# STM32N645 register map
File version: 1.0
CPU: CM55 r0p1, little endian, no MPU, FPU, vendor SysTick, 8 interrupt priority bits
Registers are 32-bit, read-write, reset 0x0 unless marked. A register's access mark holds for its fields unless they carry their own. Offsets are from the block's base; [hi:lo] are bit positions.

## SPDIFRX — SPDIF receiver interface
Base 0x40004000
Same registers: SPDIFRX_S 0x50004000
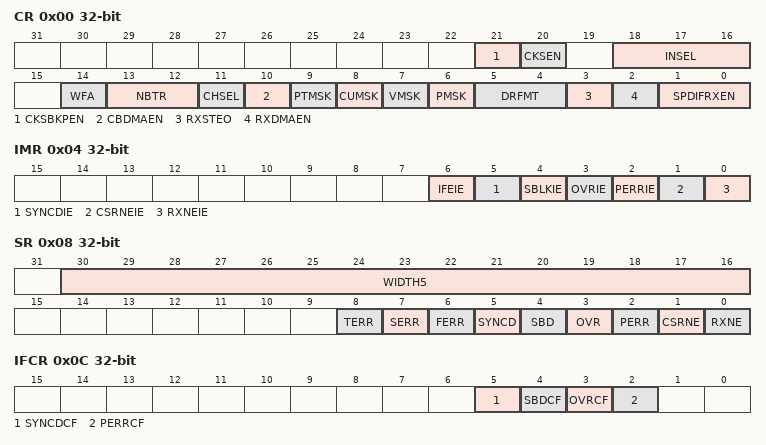
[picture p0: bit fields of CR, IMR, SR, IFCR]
0x00 CR — SPDIFRX control register
  [21] CKSBKPEN — Backup symbol clock enable
  [20] CKSEN — Symbol clock enable
  [18:16] INSEL — SPDIFRX input selection
  [14] WFA — Wait for activity less than sup>(1) less than /sup>
  [13:12] NBTR — Maximum allowed re-tries during synchronization phase less than sup>(1) less than /sup>
  [11] CHSEL — Channel selection less than sup>(1) less than /sup>
  [10] CBDMAEN — Control buffer DMA enable for control flow less than sup>(1) less than /sup>
  [9] PTMSK — Mask of preamble type bits less than sup>(1) less than /sup>
  [8] CUMSK — Mask of channel status and user bits less than sup>(1) less than /sup>
  [7] VMSK — Mask of validity bit less than sup>(1) less than /sup>
  [6] PMSK — Mask parity error bit less than sup>(1) less than /sup>
  [5:4] DRFMT — RX data format less than sup>(1) less than /sup>
  [3] RXSTEO — Stereo mode less than sup>(1) less than /sup>
  [2] RXDMAEN — Receiver DMA enable for data flow less than sup>(1) less than /sup>
  [1:0] SPDIFRXEN — Peripheral block enable less than sup>(1) less than /sup>
0x04 IMR — SPDIFRX interrupt mask register
  [6] IFEIE — Serial interface error interrupt enable
  [5] SYNCDIE — Synchronization done
  [4] SBLKIE — Synchronization block detected interrupt enable
  [3] OVRIE — Overrun error interrupt enable
  [2] PERRIE — Parity error interrupt enable
  [1] CSRNEIE — Control buffer ready interrupt enable
  [0] RXNEIE — RXNE interrupt enable
0x08 SR ro — SPDIFRX status register
  [30:16] WIDTH5 — duration of 5 symbols counted with spdifrx_ker_ck
  [8] TERR — Time-out error
  [7] SERR — Synchronization error
  [6] FERR — Framing error
  [5] SYNCD — Synchronization done
  [4] SBD — Synchronization block detected
  [3] OVR — Overrun error
  [2] PERR — Parity error
  [1] CSRNE — Control buffer register not empty
  [0] RXNE — Read data register not empty
0x0C IFCR wo — SPDIFRX interrupt flag clear register
  [5] SYNCDCF — clears the synchronization done flag
  [4] SBDCF — clears the synchronization block detected flag
  [3] OVRCF — clears the overrun error flag
  [2] PERRCF — clears the parity error flag
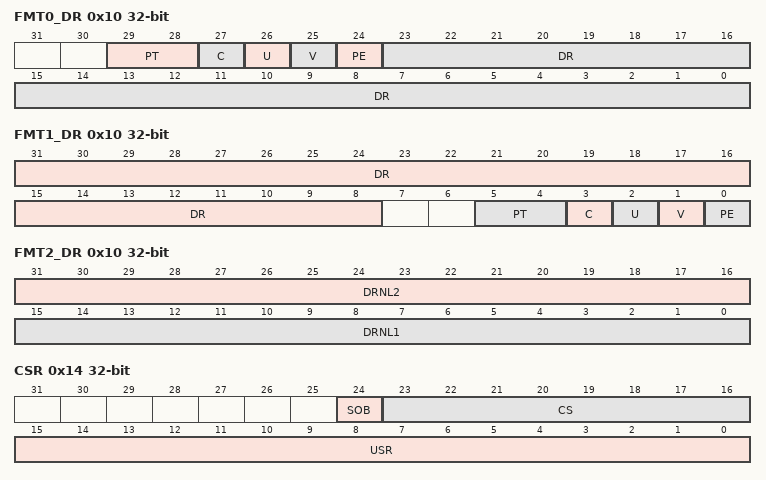
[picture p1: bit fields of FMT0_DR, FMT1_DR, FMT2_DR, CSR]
0x10 FMT0_DR ro — SPDIFRX data input register
  [29:28] PT — preamble type
  [27] C — channel status bit
  [26] U — user bit
  [25] V — validity bit
  [24] PE — parity error bit
  [23:0] DR — data value
0x10 FMT1_DR ro (alternate view of FMT0_DR) — SPDIFRX data input register
  [31:8] DR — data value
  [5:4] PT — preamble type
  [3] C — channel Status bit
  [2] U — user bit
  [1] V — validity bit
  [0] PE — parity error bit
0x10 FMT2_DR ro (alternate view of FMT0_DR) — SPDIFRX data input register
  [31:16] DRNL2 — data value
  [15:0] DRNL1 — data value
0x14 CSR ro — SPDIFRX channel status register
  [24] SOB — start of block
  [23:16] CS — channel A status information
  [15:0] USR — user data information
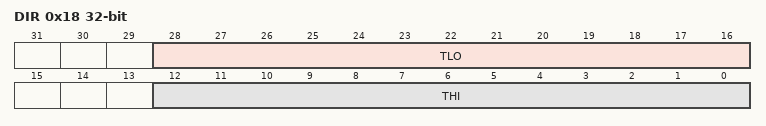
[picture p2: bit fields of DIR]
0x18 DIR ro — SPDIFRX debug information register
  [28:16] TLO — threshold LOW (TLO = 1.5 x UI / T less than sub>spdifrx_ker_ck less than /sub>)
  [12:0] THI — threshold HIGH (THI = 2.5 x UI / T less than sub>spdifrx_ker_ck less than /sub>)

## TIM6 — Basic timers
Base 0x40001000
Same registers: TIM6_S 0x50001000
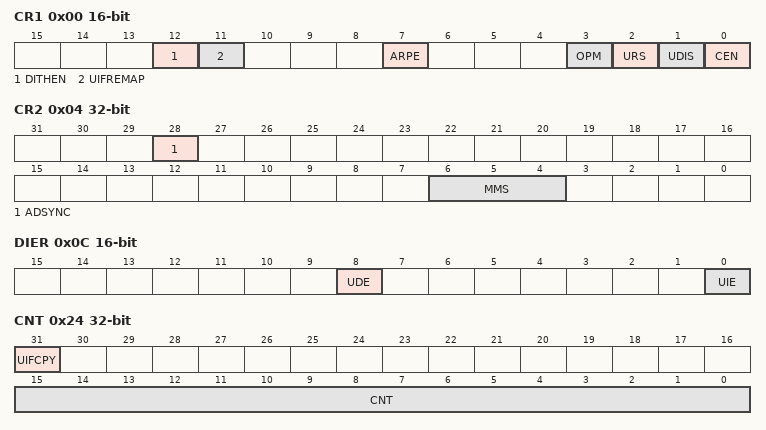
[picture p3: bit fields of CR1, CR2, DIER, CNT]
0x00 CR1 16-bit — TIM6 control register 1
  [12] DITHEN — Dithering enable
  [11] UIFREMAP — UIF status bit remapping
  [7] ARPE — Auto-reload preload enable
  [3] OPM — One-pulse mode
  [2] URS — Update request source
  [1] UDIS — Update disable
  [0] CEN — Counter enable
0x04 CR2 — TIM6 control register 2
  [28] ADSYNC — ADC synchronization
  [6:4] MMS — Master mode selection
0x0C DIER 16-bit — TIM6 DMA/Interrupt enable register
  [8] UDE — Update DMA request enable
  [0] UIE — Update interrupt enable
0x10 SR 16-bit — TIM6 status register
  [0] UIF — Update interrupt flag
0x14 EGR 16-bit wo — TIM6 event generation register
  [0] UG — Update generation
0x24 CNT access per field — TIM6 counter
  [31] UIFCPY ro — UIF copy
  [15:0] CNT rw — Counter value
0x28 PSC 16-bit — TIM6 prescaler
  [15:0] PSC — Prescaler value
0x2C ARR reset 0xFFFF — TIM6 auto-reload register
  [19:0] ARR — Auto-reload value

## TIM7 — Basic timers
Base 0x40001400
Same registers: TIM7_S 0x50001400
Registers as TIM6 (with TIM6 read as TIM7).

## TIM18 — Basic timers
Base 0x42003C00
Same registers: TIM18_S 0x52003C00
Registers as TIM6 (with TIM6 read as TIM18).
